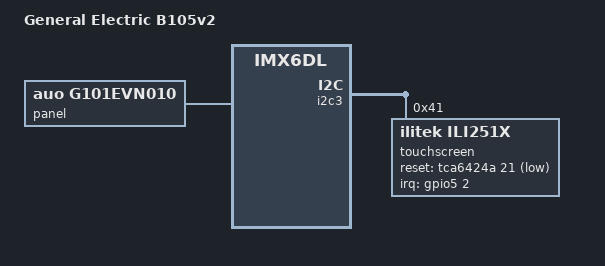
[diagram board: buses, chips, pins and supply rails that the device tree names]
// SPDX-License-Identifier: GPL-2.0 or MIT
//
// Device Tree Source for General Electric B105v2
//
// Copyright 2018-2021 General Electric Company
// Copyright 2018-2021 Collabora

/dts-v1/;
#include "imx6dl-b1x5v2.dtsi"

/ {
	model = "General Electric B105v2";
	compatible = "ge,imx6dl-b105v2", "congatec,qmx6", "fsl,imx6dl";

	panel {
		compatible = "auo,g101evn010";
	};
};

&i2c3 {
	touchscreen@41 {
		compatible = "ilitek,ili251x";
		reg = <0x41>;
		pinctrl-names = "default";
		pinctrl-0 =<&pinctrl_q7_gpio0>;
		interrupt-parent = <&gpio5>;
		interrupts = <2 IRQ_TYPE_EDGE_FALLING>;
		reset-gpios = <&tca6424a 21 GPIO_ACTIVE_LOW>;
		touchscreen-size-x = <1280>;
		touchscreen-size-y = <800>;
	};
};
